# SAMA7G54D4G device description
Architecture: CORTEX-A7; Family: SAMA; Series: SAMA7G
Registers are 32-bit, read-write, reset 0x0 unless marked. A register's access mark holds for its fields unless they carry their own. Offsets are from the block's base; [hi:lo] are bit positions; {n}, {i} and the like mark numbered series; <NAME> marks a mode.

## SPDIFTX — Sony/Philips Digital Interface
Instances: SPDIFTX 0xE1618000
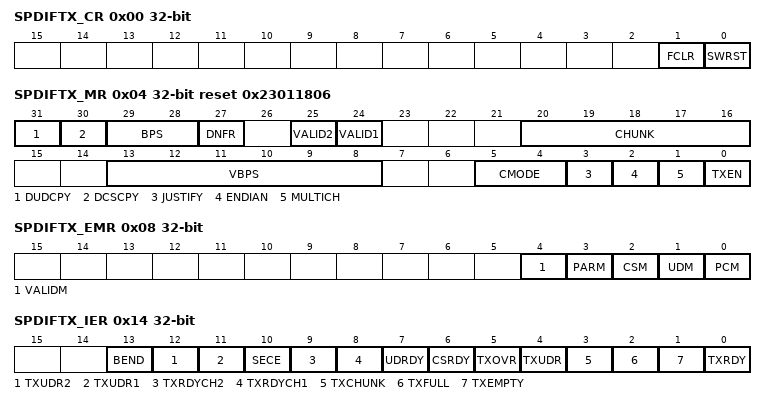
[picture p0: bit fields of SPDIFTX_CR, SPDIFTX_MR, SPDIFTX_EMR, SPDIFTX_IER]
0x00 SPDIFTX_CR wo reset not defined — SPDIF Transmitter Control Register
  [1] FCLR — FIFO clear
    0=No effect; 1=Empties Channel 1 and Channel 2 FIFOs
  [0] SWRST — Software Reset
    0=No effect; 1=Resets the SPDIFTX interface
0x04 SPDIFTX_MR reset 0x23011806 — SPDIF Transmitter Mode Register
  [31] DUDCPY — Disable User Data Copy
    0=Any data written in SPDDIFTX_CH1UDx registers is copied to SPDDIFTX_CH2UDx; 1=SPDDIFTX_CH1UDx and SPDDIFTX_CH2UDx are independant
  [30] DCSCPY — Disable Channel Status Copy
    0=Any data written in SPDDIFTX_CH1Sx registers is copied to SPDDIFTX_CH2Sx; 1=SPDDIFTX_CH1Sx and SPDDIFTX_CH2Sx are independant
  [29:28] BPS — Bytes Per Sample
    0=BYTE1 (SPDIFTX_CDR data holding operating mode is optimized for data size up to 8 bits.); 1=BYTE2 (SPDIFTX_CDR data holding operating mode is optimized for data size in range 9 to 16 bits.); 2=BYTE3 (SPDIFTX_CDR data holding operating mode is optimized for data size in range 17 to 24 bits.); 3=BYTE4 (SPDIFTX_CDR data holding operating mode is optimized for data size in range 25 to 32 bits.)
  [27] DNFR — Disable Null Frame on underrrun
    0=In case of Underrun (SPDIFTX_ISR.TXEMPTY flag is set and IP need a data) invalid frames are sent (validity bit at level '1'); 1=In case of Underrun (SPDIFTX_ISR.TXEMPTY flag is set and IP need a data) valid frames are sent
  [25] VALID2 — Validity Bit Channel 2
  [24] VALID1 — Validity Bit Channel 1
  [20:16] CHUNK — DMA Chunk Size
  [13:8] VBPS — Valid Bits Per Sample
  [5:4] CMODE — Common Audio Register Transfer Mode (if BPS=2)
    0=CHANNEL_INDEX (SPDIFTX_CDR.CDR[25:24] indicates the channel on which the data CDR[23:0] will be transmitted (1 for channel 1, 2 for channel 2).Transmitted data are located on SPDIFTX_CDR.CDR[23:0].); 1=CHANNELS_TOGGLING (The data are stored alternately in the FIFO of channel 1 and channel 2. The first sent data after a software or hardware reset is stored in the FIFO of channel 1. Transmitted data are located on SPDIFTX_CDR.CDR[23:0].); 2=COMPACT_24BIT (This mode is optimized for 24-bit data compacted on 32-bit memory space. Transmitted data are located on SPDIFTX_CDR.CDR[31:0]. The 32 bits of SPDIFTX_CDR are used and contains one or more channel data.); 3=CONTROL_BITS (Control bits (preamble, validity, user data, channel status, parity) can be managed by writing SPDIFTX_CDR.CDR[31:24] depending on SPDIFTX_EMR configuration. The data are stored alternately in the FIFO of channel 1 and channel 2. The first sent data after a software or hardware reset is stored in the FIFO of channel 1. Transmitted data are located on SPDIFTX_CDR.CDR[23:0].)
  [3] JUSTIFY — Data Justification
    0=LSB (Least Significant Bit justification. The valid bits of the signal are aligned on the least-significant bits of the container.); 1=MSB (Most Significant Bit justification. The valid bits of the signal are aligned on the most-significant bits of the container.)
  [2] ENDIAN — Data Word Endian Mode
    0=LITTLE (Little-endian mode.); 1=BIG (Big-endian mode.)
  [1] MULTICH — Multichannel Transfer
    0=MONO (One channel is sent on channel 1 to SPDIFTX_TX and is copied on channel 2.); 1=DUAL (Two separate channels are sent to SPDIFTX_TX.)
  [0] TXEN — SPDIFTX Transmit Enable
    0=DISABLE (SPDIFTX transmission is disabled.); 1=ENABLE (SPDIFTX transmission is enabled.)
0x08 SPDIFTX_EMR — SPDIF Transmitter Extended Mode Register
  [4] VALIDM — Validity Bit Mode
    0=Validity bit is defined by SPDIFTX_MR.VALID1 and SPDIFTX_MR.VALID2 values; 1=Validity bit is defined by the SPDIFTX_CDR.VALID bit
  [3] PARM — Parity Mode
    0=Parity bit is automatically set by the SPDIFTX; 1=Parity bit sent is defined by SPDIFTX_CDR.PAR bit
  [2] CSM — Channel Status Mode
    0=Channel status is defined by SPDIFTX_CHxCSx registers; 1=Channel status is defined by SPDIFTX_CDR.CS bit
  [1] UDM — User Data Mode
    0=User data is defined by SPDIFTX_CHxUDx registers; 1=User data is defined by SPDIFTX_CDR.UD bit
  [0] PCM — Preamble Code Mode
    0=Preamble code is generated automatically by the SPDIFTX; 1=Preamble code is defined by SPDIFTX_CDR.PC field
0x0C SPDIFTX_CDR wo reset not defined — SPDIF Transmitter Common Data Register
  [29:28] PC <CONTROL_BITS> — Preamble Code
    0=PREAMBLE_B (Preamble "B" will be sent.); 1=PREAMBLE_M (Preamble "M" will be sent.); 2=PREAMBLE_W (Preamble "W" will be sent.)
  [27] PAR <CONTROL_BITS> — Parity
    0=Correct parity bit will be sent; 1=Wrong parity bit will be sent
  [26] CS <CONTROL_BITS> — Channel Status
  [25] UD <CONTROL_BITS> — User Data
  [24] VALID <CONTROL_BITS> — Validity Bit
    0=Sample is valid for analog conversion; 1=Sample is not valid for analog conversion
  [23:0] CDR <CONTROL_BITS> — Common Data Register
  [31:0] CDR <DEFAULT> — Common Data Register
0x10 SPDIFTX_SR ro reset not defined — SPDIF Transmitter Status Register
  [0] ENS — Enable Status
    0=SPDIF core is disabled; 1=SPDIF core is enabled
0x14 SPDIFTX_IER wo reset not defined (atomic set of SPDIFTX_IMR) — SPDIF Transmitter Interrupt Enable Register
  [13] BEND — Block End Interrupt Enable
  [12] TXUDR2 — Channel 2 Transmit Under Flow Interrupt Enable
  [11] TXUDR1 — Channel 1 Transmit Under Flow Interrupt Enable
  [10] SECE — Security Report Interrupt Enable
  [9] TXRDYCH2 — Transmit Ready Channel 2 Interrupt Enable
  [8] TXRDYCH1 — Transmit Ready Channel 1 Interrupt Enable
  [7] UDRDY — User Data Ready Interrupt Enable
  [6] CSRDY — Channel Status Ready Interrupt Enable
  [5] TXOVR — Transmit Over Flow Interrupt Enable
  [4] TXUDR — Transmit Under Flow Interrupt Enable
  [3] TXCHUNK — Transmit FIFO Chunk Size Empty Interrupt Enable
  [2] TXFULL — Transmit FIFO Full Interrupt Enable
  [1] TXEMPTY — Transmit FIFO Empty Interrupt Enable
  [0] TXRDY — Transmit Ready Interrupt Enable
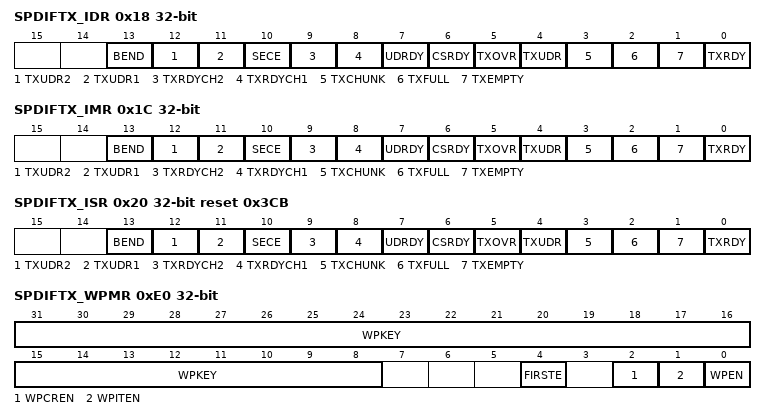
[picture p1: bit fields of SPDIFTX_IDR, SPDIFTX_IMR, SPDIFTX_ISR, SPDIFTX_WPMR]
0x18 SPDIFTX_IDR wo reset not defined (atomic clear of SPDIFTX_IMR) — SPDIF Transmitter Interrupt Disable Register
  [13] BEND — Block End Interrupt Disable
  [12] TXUDR2 — Channel 2 Transmit Under Flow Interrupt Disable
  [11] TXUDR1 — Channel 1 Transmit Under Flow Interrupt Disable
  [10] SECE — Security Report Interrupt Disable
  [9] TXRDYCH2 — Transmit Ready Channel 2 Interrupt Disable
  [8] TXRDYCH1 — Transmit Ready Channel 1 Interrupt Disable
  [7] UDRDY — User Data Ready Interrupt Disable
  [6] CSRDY — Channel Status Ready Interrupt Disable
  [5] TXOVR — Transmit Over Flow Interrupt Disable
  [4] TXUDR — Transmit Under Flow Interrupt Disable
  [3] TXCHUNK — Transmit FIFO Chunk Size Empty Interrupt Disable
  [2] TXFULL — Transmit FIFO Full Interrupt Disable
  [1] TXEMPTY — Transmit FIFO Empty Interrupt Disable
  [0] TXRDY — Transmit Ready Interrupt Disable
0x1C SPDIFTX_IMR ro — SPDIF Transmitter Interrupt Mask Register
  [13] BEND — Block End Interrupt Mask
  [12] TXUDR2 — Channel 2 Transmit Under Flow Interrupt Mask
  [11] TXUDR1 — Channel 1 Transmit Under Flow Interrupt Mask
  [10] SECE — Security Report Interrupt Mask
  [9] TXRDYCH2 — Transmit Ready Channel 2 Interrupt Mask
  [8] TXRDYCH1 — Transmit Ready Channel 1 Interrupt Mask
  [7] UDRDY — User Data Ready Interrupt Mask
  [6] CSRDY — Channel Status Ready Interrupt Mask
  [5] TXOVR — Transmit Over Flow Interrupt Mask
  [4] TXUDR — Transmit Under Flow Interrupt Mask
  [3] TXCHUNK — Transmit FIFO Chunk Size Empty Interrupt Mask
  [2] TXFULL — Transmit FIFO Full Interrupt Mask
  [1] TXEMPTY — Transmit FIFO Empty Interrupt Mask
  [0] TXRDY — Transmit Ready Interrupt Mask
0x20 SPDIFTX_ISR ro reset 0x3CB — SPDIF Transmitter Interrupt Status Register
  [13] BEND — Block End Status (cleared on read)
    0=No Block End event occurred since last SPDIFTX_ISR read; 1=At least one Block End event occurred since last SPDIFTX_ISR read
  [12] TXUDR2 — Channel 2 Transmit Under Flow Status (cleared on read)
  [11] TXUDR1 — Channel 1 Transmit Under Flow Status (cleared on read)
  [10] SECE — Security Report Status (cleared on read)
  [9] TXRDYCH2 — Transmit Ready Status Channel 2 (cleared when channel 2 FIFO is full)
  [8] TXRDYCH1 — Transmit Ready Status Channel 1 (cleared when channel 1 FIFO is full)
  [7] UDRDY — User Data Ready Status (cleared writing SPDIFTX_CHxUDR0 register)
  [6] CSRDY — Channel Status Ready Status (cleared writing SPDIFTX_CHxSR0 register)
  [5] TXOVR — Transmit Over Flow Status (cleared on read)
  [4] TXUDR — Transmit Under Flow Status (cleared on read)
  [3] TXCHUNK — Transmit FIFO Chunk Size Empty Status (cleared by writing CHUNK data in SPDIFTX_CDR)
  [2] TXFULL — Transmit FIFO Full Status (cleared when data are sent or writing the SPDIFTX_CR.FCLR bit)
  [1] TXEMPTY — Transmit FIFO Empty Status (cleared by writing SPDIFTX_CDR, SPDIFTX_AW1 or SPDIFTX_AW2 register)
  [0] TXRDY — Transmit Ready Status (cleared when both channel 1 and 2 FIFOs are full)
0x24 SPDIFTX_SFI ro reset 0x17F — SPDIF Transmitter Subframe Index Register
  [9:0] SFI — Transmit Subframe Index
{0x30+4i} SPDIFTX_AW[{i}] (i=0..1) wo — SPDIF Transmitter Channel 1 Audio Word
  [31:0] AW — Audio Word Channel 1
{0x50+4i} SPDIFTX_CH1UD[{i}] (i=0..5) — SPDIF Transmitter User Data 1 Register x
  [31:0] CHUD — Channel 1 User Data Word
{0x68+4i} SPDIFTX_CH2UD[{i}] (i=0..5) — SPDIF Transmitter User Data 2 Register x
  [31:0] CHUD — Channel 2 User Data Word
{0x80+4i} SPDIFTX_CH1S[{i}] (i=0..5) — SPDIF Transmitter Channel Status 1 Register x
  [31:0] CHS — Channel 1 Status Word
{0x98+4i} SPDIFTX_CH2S[{i}] (i=0..5) — SPDIF Transmitter Channel Status 2 Register x
  [31:0] CHS — Channel 2 Status Word
0xE0 SPDIFTX_WPMR — SPDIF Transmitter Write Protection Mode Register
  [31:8] WPKEY — Write Protection Key
    0x444946=PASSWD (Writing any other value in this field aborts the write operation of the WPEN bit. Always reads as 0.)
  [4] FIRSTE — First Error Report Enable
    0=The last write protection violation source is reported in SPDIFTX_WPSR.WPSRC and the last software control error type is reported in SPDIFTX_WPSR.SWETYP. The SPDIFTX_ISR.SECE flag is set at the first error occurrence within a series.; 1=Only the first write protection violation source is reported in SPDIFTX_WPSR.WPSRC and only the first software control error type is reported in SPDIFTX_WPSR.SWETYP. The SPDIFTX_ISR.SECE flag is set at the first error occurrence within a series.
  [2] WPCREN — Write Protection Control Register Enable
    0=Disables the write protection on the Control register if WPKEY corresponds to 0x444946; 1=Enables the write protection on the Control register if WPKEY corresponds to 0x444946
  [1] WPITEN — Write Protection Interrupt Enable
    0=Disables the write protection on Interrupt registers if WPKEY corresponds to 0x444946; 1=Enables the write protection on Interrupt registers if WPKEY corresponds to 0x444946
  [0] WPEN — Write Protection Enable
    0=Disables the write protection if WPKEY corresponds to 0x444946 (DIF in ASCII); 1=Enables the write protection if WPKEY corresponds to 0x444946 (DIF in ASCII)
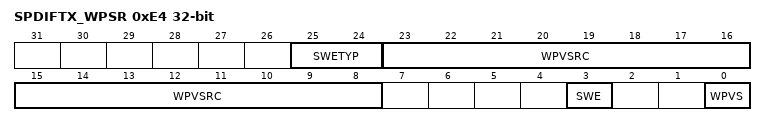
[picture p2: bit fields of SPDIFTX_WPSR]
0xE4 SPDIFTX_WPSR ro — SPDIF Transmitter Write Protection Status Register
  [25:24] SWETYP — Software Error Type (cleared on read)
    0=READ_WO (A write-only register has been read (warning).); 1=WRITE_RO (A write access has been performed on a read-only register (warning).); 2=UNDEF_RW (Access to an undefined address (warning).)
  [23:8] WPVSRC — Write Protection Violation Source
  [3] SWE — Software Control Error (cleared on read)
    0=No software error has occurred since the last read of SPDIFTX_WPSR; 1=A software error has occurred since the last read of SPDIFTX_WPSR. The field SWETYP details the type of software error; the associated incorrect software access is reported in the field WPSRC (if WPVS=0).
  [0] WPVS — Write Protection Violation Status (cleared on read)
    0=No write protection violation has occurred since the last read of the QSPI_WPSR; 1=A write protection violation has occurred since the last read of the QSPI_WPSR. If this violation is an unauthorized attempt to write a protected register, the associated violation is reported into field WPVSRC.
